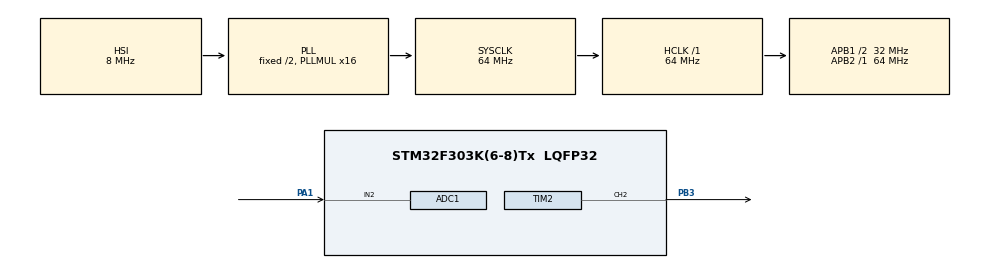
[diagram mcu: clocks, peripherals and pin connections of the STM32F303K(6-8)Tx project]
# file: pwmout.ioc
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ADC1.Channel-0\#ChannelRegularConversion=ADC_CHANNEL_2
ADC1.ContinuousConvMode=DISABLE
ADC1.ExternalTrigConv=ADC_EXTERNALTRIGCONV_T2_CC2
ADC1.NbrOfConversionFlag=1
ADC1.Offset-0\#ChannelRegularConversion=0
ADC1.OffsetNumber-0\#ChannelRegularConversion=ADC_OFFSET_NONE
ADC1.Rank-0\#ChannelRegularConversion=1
ADC1.SamplingTime-0\#ChannelRegularConversion=ADC_SAMPLETIME_601CYCLES_5
ADC1.SubFamily=STM32F303x8
ADC1.master=1
Mcu.Family=STM32F3
Mcu.Name=STM32F303K(6-8)Tx
Mcu.Package=LQFP32
NVIC.PriorityGroup=NVIC_PRIORITYGROUP_4
NVIC.TIM2_IRQn=true\:0\:0\:false\:false\:true
PA1.Mode=IN2-Single-Ended
PA1.Signal=ADC1_IN2
PA13.GPIO_Label=SWDIO
PA13.Signal=SYS_JTMS-SWDIO
PA14.GPIO_Label=SWCLK
PA14.Signal=SYS_JTCK-SWCLK
PA15.GPIO_Label=VCP_RX
PA15.Signal=USART2_RX
PA2.GPIO_Label=VCP_TX
PA2.Signal=USART2_TX
PB3.Signal=S_TIM2_CH2
PF0\ /\ OSC_IN.GPIO_Label=MCO
PF0\ /\ OSC_IN.Signal=RCC_OSC_IN
ProjectManager.HeapSize=0x200
ProjectManager.StackSize=0x400
ProjectManager.TargetToolchain=SW4STM32
RCC.AHBFreq_Value=64000000
RCC.APB1CLKDivider=RCC_HCLK_DIV2
RCC.APB1Freq_Value=32000000
RCC.APB1TimFreq_Value=64000000
RCC.APB2Freq_Value=64000000
RCC.APB2TimFreq_Value=64000000
RCC.CortexFreq_Value=64000000
RCC.HCLKFreq_Value=64000000
RCC.HSE_VALUE=8000000
RCC.HSI_VALUE=8000000
RCC.PLLMUL=RCC_PLL_MUL16
RCC.SYSCLKFreq_VALUE=64000000
RCC.SYSCLKSourceVirtual=RCC_SYSCLKSOURCE_PLLCLK
SH.S_TIM2_CH2.0=TIM2_CH2,PWM Generation2 CH2
TIM2.Channel-PWM\ Generation2\ CH2=TIM_CHANNEL_2
TIM2.Period=1280000
TIM2.Pulse-PWM\ Generation2\ CH2=1280000/2
board=NUCLEO-F303K8

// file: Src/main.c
/**
  ******************************************************************************
  * File Name          : main.c
  * Description        : Main program body
  ******************************************************************************
  *
  * COPYRIGHT(c) 2017 STMicroelectronics
  *
  * Redistribution and use in source and binary forms, with or without modification,
  * are permitted provided that the following conditions are met:
  *   1. Redistributions of source code must retain the above copyright notice,
  *      this list of conditions and the following disclaimer.
  *   2. Redistributions in binary form must reproduce the above copyright notice,
  *      this list of conditions and the following disclaimer in the documentation
  *      and/or other materials provided with the distribution.
  *   3. Neither the name of STMicroelectronics nor the names of its contributors
  *      may be used to endorse or promote products derived from this software
  *      without specific prior written permission.
  *
  * THIS SOFTWARE IS PROVIDED BY THE COPYRIGHT HOLDERS AND CONTRIBUTORS "AS IS"
  * AND ANY EXPRESS OR IMPLIED WARRANTIES, INCLUDING, BUT NOT LIMITED TO, THE
  * IMPLIED WARRANTIES OF MERCHANTABILITY AND FITNESS FOR A PARTICULAR PURPOSE ARE
  * DISCLAIMED. IN NO EVENT SHALL THE COPYRIGHT HOLDER OR CONTRIBUTORS BE LIABLE
  * FOR ANY DIRECT, INDIRECT, INCIDENTAL, SPECIAL, EXEMPLARY, OR CONSEQUENTIAL
  * DAMAGES (INCLUDING, BUT NOT LIMITED TO, PROCUREMENT OF SUBSTITUTE GOODS OR
  * SERVICES; LOSS OF USE, DATA, OR PROFITS; OR BUSINESS INTERRUPTION) HOWEVER
  * CAUSED AND ON ANY THEORY OF LIABILITY, WHETHER IN CONTRACT, STRICT LIABILITY,
  * OR TORT (INCLUDING NEGLIGENCE OR OTHERWISE) ARISING IN ANY WAY OUT OF THE USE
  * OF THIS SOFTWARE, EVEN IF ADVISED OF THE POSSIBILITY OF SUCH DAMAGE.
  *
  ******************************************************************************
  */
#include "main.h"
#include "stm32f3xx_hal.h"
#include "adc.h"
#include "tim.h"
#include "gpio.h"

/* USER CODE BEGIN PV */
/* Private variables ---------------------------------------------------------*/

/* USER CODE END PV */

void SystemClock_Config(void);
void Error_Handler(void);

/* USER CODE BEGIN PFP */
/* Private function prototypes -----------------------------------------------*/

/* USER CODE END PFP */

int main(void)
{

  /* MCU Configuration----------------------------------------------------------*/

  /* Reset of all peripherals, Initializes the Flash interface and the Systick. */
  HAL_Init();

  /* Configure the system clock */
  SystemClock_Config();

  /* Initialize all configured peripherals */
  MX_GPIO_Init();
  MX_ADC1_Init();
  MX_TIM2_Init();

  /* USER CODE BEGIN 2 */
  adc_start_cal();
  adc_start();
  pwm_start();
  /* USER CODE END 2 */

  /* Infinite loop */
  while (1)
  {

  }

}

/** System Clock Configuration
*/
void SystemClock_Config(void)
{

  RCC_OscInitTypeDef RCC_OscInitStruct;
  RCC_ClkInitTypeDef RCC_ClkInitStruct;
  RCC_PeriphCLKInitTypeDef PeriphClkInit;

    /**Initializes the CPU, AHB and APB busses clocks
    */
  RCC_OscInitStruct.OscillatorType = RCC_OSCILLATORTYPE_HSI;
  RCC_OscInitStruct.HSIState = RCC_HSI_ON;
  RCC_OscInitStruct.HSICalibrationValue = 16;
  RCC_OscInitStruct.PLL.PLLState = RCC_PLL_ON;
  RCC_OscInitStruct.PLL.PLLSource = RCC_PLLSOURCE_HSI;
  RCC_OscInitStruct.PLL.PLLMUL = RCC_PLL_MUL16;
  if (HAL_RCC_OscConfig(&RCC_OscInitStruct) != HAL_OK)
  {
    Error_Handler();
  }

    /**Initializes the CPU, AHB and APB busses clocks
    */
  RCC_ClkInitStruct.ClockType = RCC_CLOCKTYPE_HCLK|RCC_CLOCKTYPE_SYSCLK
                              |RCC_CLOCKTYPE_PCLK1|RCC_CLOCKTYPE_PCLK2;
  RCC_ClkInitStruct.SYSCLKSource = RCC_SYSCLKSOURCE_PLLCLK;
  RCC_ClkInitStruct.AHBCLKDivider = RCC_SYSCLK_DIV1;
  RCC_ClkInitStruct.APB1CLKDivider = RCC_HCLK_DIV2;
  RCC_ClkInitStruct.APB2CLKDivider = RCC_HCLK_DIV1;

  if (HAL_RCC_ClockConfig(&RCC_ClkInitStruct, FLASH_LATENCY_2) != HAL_OK)
  {
    Error_Handler();
  }

  PeriphClkInit.PeriphClockSelection = RCC_PERIPHCLK_ADC12;
  PeriphClkInit.Adc12ClockSelection = RCC_ADC12PLLCLK_DIV1;
  if (HAL_RCCEx_PeriphCLKConfig(&PeriphClkInit) != HAL_OK)
  {
    Error_Handler();
  }

    /**Configure the Systick interrupt time
    */
  HAL_SYSTICK_Config(HAL_RCC_GetHCLKFreq()/1000);

    /**Configure the Systick
    */
  HAL_SYSTICK_CLKSourceConfig(SYSTICK_CLKSOURCE_HCLK);

  /* SysTick_IRQn interrupt configuration */
  HAL_NVIC_SetPriority(SysTick_IRQn, 0, 0);
}

void Error_Handler(void)
{
  while(1)
  {
  }
}

/************************ (C) COPYRIGHT STMicroelectronics *****END OF FILE****/
